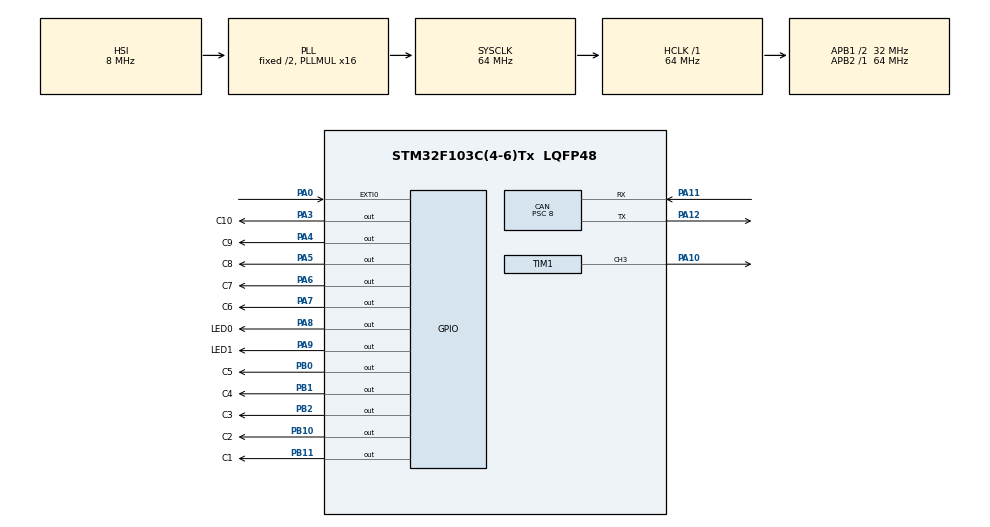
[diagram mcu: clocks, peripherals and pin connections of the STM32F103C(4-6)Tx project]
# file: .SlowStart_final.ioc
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CAN.BS1=CAN_BS1_2TQ
CAN.BS2=CAN_BS2_1TQ
CAN.CalculateBaudRate=1000000
CAN.CalculateTimeBit=1000
CAN.CalculateTimeQuantum=250.0
CAN.Mode=CAN_MODE_NORMAL
CAN.Prescaler=8
Mcu.Family=STM32F1
Mcu.Name=STM32F103C(4-6)Tx
Mcu.Package=LQFP48
NVIC.CAN1_RX1_IRQn=true\:2\:0\:true\:false\:true\:true\:true\:true
NVIC.PriorityGroup=NVIC_PRIORITYGROUP_4
NVIC.TIM1_UP_IRQn=true\:0\:0\:true\:false\:true\:true\:true\:true
NVIC.TIM2_IRQn=true\:3\:0\:true\:false\:true\:true\:true\:true
NVIC.TIM3_IRQn=true\:1\:0\:true\:false\:true\:true\:true\:true
NVIC.USB_LP_CAN1_RX0_IRQn=true\:2\:0\:true\:false\:true\:true\:true\:true
PA0-WKUP.GPIO_ModeDefaultEXTI=GPIO_MODE_IT_FALLING
PA0-WKUP.GPIO_PuPd=GPIO_PULLUP
PA0-WKUP.Signal=GPXTI0
PA10.Signal=S_TIM1_CH3
PA11.Mode=CAN_Activate
PA11.Signal=CAN_RX
PA12.Mode=CAN_Activate
PA12.Signal=CAN_TX
PA13.Mode=Serial_Wire
PA13.Signal=SYS_JTMS-SWDIO
PA14.Mode=Serial_Wire
PA14.Signal=SYS_JTCK-SWCLK
PA3.GPIO_Label=C10
PA3.GPIO_PuPd=GPIO_PULLDOWN
PA3.GPIO_Speed=GPIO_SPEED_FREQ_HIGH
PA3.PinState=GPIO_PIN_RESET
PA3.Signal=GPIO_Output
PA4.GPIO_Label=C9
PA4.GPIO_PuPd=GPIO_PULLDOWN
PA4.GPIO_Speed=GPIO_SPEED_FREQ_HIGH
PA4.Signal=GPIO_Output
PA5.GPIO_Label=C8
PA5.GPIO_PuPd=GPIO_PULLDOWN
PA5.GPIO_Speed=GPIO_SPEED_FREQ_HIGH
PA5.Signal=GPIO_Output
PA6.GPIO_Label=C7
PA6.GPIO_PuPd=GPIO_PULLDOWN
PA6.GPIO_Speed=GPIO_SPEED_FREQ_HIGH
PA6.Signal=GPIO_Output
PA7.GPIO_Label=C6
PA7.GPIO_PuPd=GPIO_PULLDOWN
PA7.GPIO_Speed=GPIO_SPEED_FREQ_HIGH
PA7.Signal=GPIO_Output
PA8.GPIO_Label=LED0
PA8.GPIO_PuPd=GPIO_PULLDOWN
PA8.GPIO_Speed=GPIO_SPEED_FREQ_HIGH
PA8.PinState=GPIO_PIN_SET
PA8.Signal=GPIO_Output
PA9.GPIO_Label=LED1
PA9.GPIO_PuPd=GPIO_PULLDOWN
PA9.GPIO_Speed=GPIO_SPEED_FREQ_HIGH
PA9.PinState=GPIO_PIN_SET
PA9.Signal=GPIO_Output
PB0.GPIO_Label=C5
PB0.GPIO_PuPd=GPIO_PULLDOWN
PB0.GPIO_Speed=GPIO_SPEED_FREQ_HIGH
PB0.Signal=GPIO_Output
PB1.GPIO_Label=C4
PB1.GPIO_PuPd=GPIO_PULLDOWN
PB1.GPIO_Speed=GPIO_SPEED_FREQ_HIGH
PB1.Signal=GPIO_Output
PB10.GPIO_Label=C2
PB10.GPIO_PuPd=GPIO_PULLDOWN
PB10.GPIO_Speed=GPIO_SPEED_FREQ_HIGH
PB10.Signal=GPIO_Output
PB11.GPIO_Label=C1
PB11.GPIO_PuPd=GPIO_PULLDOWN
PB11.GPIO_Speed=GPIO_SPEED_FREQ_HIGH
PB11.Signal=GPIO_Output
PB2.GPIO_Label=C3
PB2.GPIO_PuPd=GPIO_PULLDOWN
PB2.GPIO_Speed=GPIO_SPEED_FREQ_HIGH
PB2.Signal=GPIO_Output
ProjectManager.HeapSize=0x200
ProjectManager.StackSize=0x400
ProjectManager.TargetToolchain=STM32CubeIDE
RCC.AHBFreq_Value=64000000
RCC.APB1CLKDivider=RCC_HCLK_DIV2
RCC.APB1Freq_Value=32000000
RCC.APB1TimFreq_Value=64000000
RCC.APB2Freq_Value=64000000
RCC.APB2TimFreq_Value=64000000
RCC.HCLKFreq_Value=64000000
RCC.PLLMUL=RCC_PLL_MUL16
RCC.SYSCLKFreq_VALUE=64000000
RCC.SYSCLKSource=RCC_SYSCLKSOURCE_PLLCLK
RCC.USBFreq_Value=64000000
SH.S_TIM1_CH3.0=TIM1_CH3,PWM Generation3 CH3
TIM1.Channel-PWM\ Generation3\ CH3=TIM_CHANNEL_3
TIM1.Period=3200
TIM1.Pulse-PWM\ Generation3\ CH3=1000
TIM2.Period=32000
TIM2.Prescaler=999
TIM3.Period=32000
VP_TIM1_VS_ClockSourceINT.Mode=Internal
VP_TIM2_VS_ClockSourceINT.Mode=Internal
VP_TIM3_VS_ClockSourceINT.Mode=Internal
board=custom

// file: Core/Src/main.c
/* USER CODE BEGIN Header */
/**
  ******************************************************************************
  * @file           : main.c
  * @brief          : Main program body
  ******************************************************************************
  * @attention
  *
  * Copyright (c) 2024 STMicroelectronics.
  * All rights reserved.
  *
  * This software is licensed under terms that can be found in the LICENSE file
  * in the root directory of this software component.
  * If no LICENSE file comes with this software, it is provided AS-IS.
  *
  ******************************************************************************
  */
/* USER CODE END Header */
#include "main.h"
#include "can.h"
#include "tim.h"
#include "gpio.h"

/* USER CODE BEGIN Includes */
#include "can.h"
#include "slowStart.h"
/* USER CODE END Includes */

void SystemClock_Config(void);

int main(void) {

    /* MCU Configuration--------------------------------------------------------*/

    /* Reset of all peripherals, Initializes the Flash interface and the Systick. */
    HAL_Init();

    /* Configure the system clock */
    SystemClock_Config();

    /* Initialize all configured peripherals */
    MX_GPIO_Init();
    MX_CAN_Init();
    MX_TIM1_Init();
    MX_TIM3_Init();
    MX_TIM2_Init();
    /* USER CODE BEGIN 2 */
    HAL_TIM_Base_Start_IT(&htim1);
    HAL_TIM_PWM_Start(&htim1, TIM_CHANNEL_3);
    htim1.Instance->CCR3 = htim1.Init.Period;
    HAL_TIM_Base_Start_IT(&htim3);
    HAL_TIM_Base_Start_IT(&htim2);
    CAN1_Filter_Init();

    if (HAL_CAN_ActivateNotification(&hcan, CAN_IT_RX_FIFO0_MSG_PENDING) != HAL_OK) {
        Error_Handler();
    }
    if (HAL_CAN_Start(&hcan) != HAL_OK) {
        Error_Handler();
    }

    //HAL_TIM_Base_Start_IT(&htim1);
    all_set(CLOSE_MODE);
    /* USER `CODE END 2 */

    /* Infinite loop */
    /* USER CODE BEGIN WHILE */
    while (1) {
        HAL_Delay(1000);
        /* USER CODE END WHILE */

    }
}

void SystemClock_Config(void) {
    RCC_OscInitTypeDef RCC_OscInitStruct = {0};
    RCC_ClkInitTypeDef RCC_ClkInitStruct = {0};

    /** Initializes the RCC Oscillators according to the specified parameters
    * in the RCC_OscInitTypeDef structure.
    */
    RCC_OscInitStruct.OscillatorType = RCC_OSCILLATORTYPE_HSI;
    RCC_OscInitStruct.HSIState = RCC_HSI_ON;
    RCC_OscInitStruct.HSICalibrationValue = RCC_HSICALIBRATION_DEFAULT;
    RCC_OscInitStruct.PLL.PLLState = RCC_PLL_ON;
    RCC_OscInitStruct.PLL.PLLSource = RCC_PLLSOURCE_HSI_DIV2;
    RCC_OscInitStruct.PLL.PLLMUL = RCC_PLL_MUL16;
    if (HAL_RCC_OscConfig(&RCC_OscInitStruct) != HAL_OK) {
        Error_Handler();
    }

    /** Initializes the CPU, AHB and APB buses clocks
    */
    RCC_ClkInitStruct.ClockType = RCC_CLOCKTYPE_HCLK | RCC_CLOCKTYPE_SYSCLK
                                  | RCC_CLOCKTYPE_PCLK1 | RCC_CLOCKTYPE_PCLK2;
    RCC_ClkInitStruct.SYSCLKSource = RCC_SYSCLKSOURCE_PLLCLK;
    RCC_ClkInitStruct.AHBCLKDivider = RCC_SYSCLK_DIV1;
    RCC_ClkInitStruct.APB1CLKDivider = RCC_HCLK_DIV2;
    RCC_ClkInitStruct.APB2CLKDivider = RCC_HCLK_DIV1;

    if (HAL_RCC_ClockConfig(&RCC_ClkInitStruct, FLASH_LATENCY_2) != HAL_OK) {
        Error_Handler();
    }
}

void Error_Handler(void) {
    __disable_irq();
    while (1) {
    }
}
